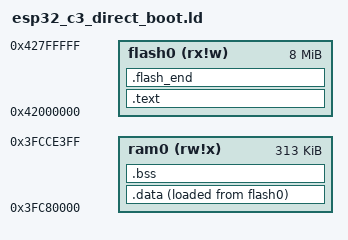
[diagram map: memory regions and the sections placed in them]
/*
 * This file was auto-generated by microzig
 *
 * Target CPU:  generic_rv32
 * Target Chip: ESP32-C3
 */

ENTRY(microzig_main);

MEMORY
{
  flash0    (rx!w) : ORIGIN = 0x42000000, LENGTH = 0x00800000
  ram0      (rw!x) : ORIGIN = 0x3FC80000, LENGTH = 313K
}

SECTIONS
{
  .text :
  {
     KEEP(*(microzig_flash_start))
     KEEP(*(.trap))
     *(.text*)
  } > flash0

  .data :
  {
     microzig_data_start = .;
     *(.sdata*)
     *(.data*)
     *(.rodata*)
     microzig_data_end = .;
  } > ram0 AT> flash0

  .bss (NOLOAD) :
  {
      microzig_bss_start = .;
      *(.bss*)
      *(.sbss*)
      microzig_bss_end = .;
  } > ram0

  .flash_end :
  {
      PROVIDE(microzig_flash_end = .);
  } > flash0

  microzig_data_load_start = LOADADDR(.data);
  PROVIDE(__global_pointer$ = microzig_data_start + 0x800);
}
